AUTOSAR XML (schema 4-2-2)
package /STELLANTIS/EPT/ASWCs
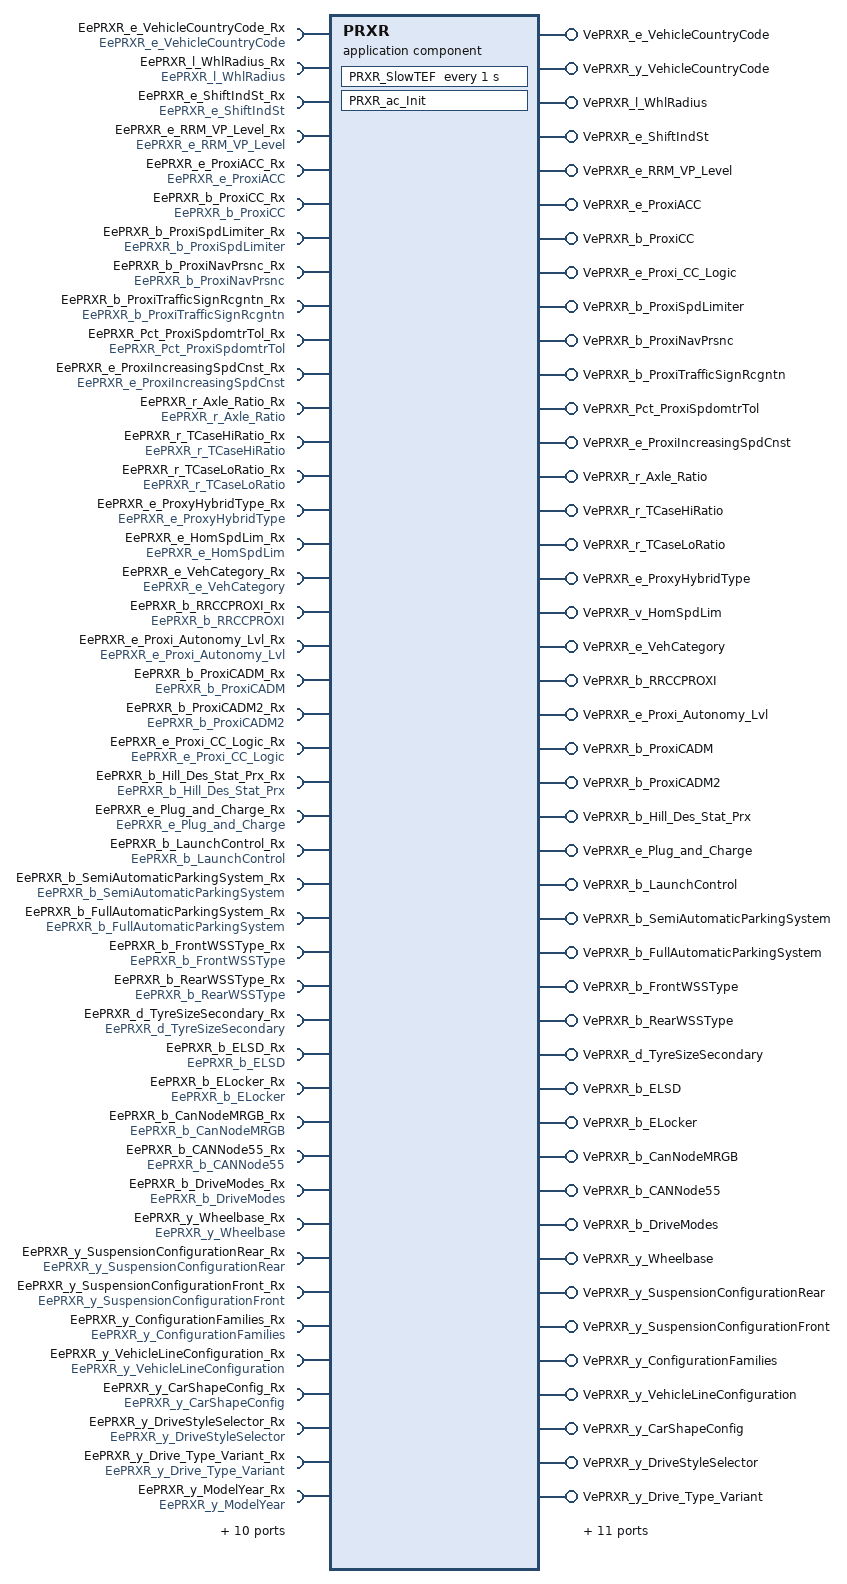
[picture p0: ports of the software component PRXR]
  application sw component type PRXR
    55 x provide port:
      VePRXR_e_VehicleCountryCode: nonqueued-sender-com-spec{data-element=Value, init-value=CePRXR_e_VCC_OTHERS}, provided-interface=VePRXR_e_VehicleCountryCode
      VePRXR_y_VehicleCountryCode: nonqueued-sender-com-spec{data-element=Value, init-value=0}, provided-interface=VePRXR_y_VehicleCountryCode
      VePRXR_l_WhlRadius: nonqueued-sender-com-spec{data-element=Value, init-value=0}, provided-interface=VePRXR_l_WhlRadius
      VePRXR_e_ShiftIndSt: nonqueued-sender-com-spec{data-element=Value, init-value=CePRXR_e_NotPresent}, provided-interface=VePRXR_e_ShiftIndSt
      VePRXR_e_RRM_VP_Level: nonqueued-sender-com-spec{data-element=Value, init-value=CePRXR_e_RRM_VP_Absent}, provided-interface=VePRXR_e_RRM_VP_Level
      VePRXR_e_ProxiACC: nonqueued-sender-com-spec{data-element=Value, init-value=CePRXR_e_ACC_Absent}, provided-interface=VePRXR_e_ProxiACC
      VePRXR_b_ProxiCC: nonqueued-sender-com-spec{data-element=Value, init-value=0}, provided-interface=VePRXR_b_ProxiCC
      VePRXR_e_Proxi_CC_Logic: nonqueued-sender-com-spec{data-element=Value, init-value=CePRXR_e_Logic1}, provided-interface=VePRXR_e_Proxi_CC_Logic
      VePRXR_b_ProxiSpdLimiter: nonqueued-sender-com-spec{data-element=Value, init-value=0}, provided-interface=VePRXR_b_ProxiSpdLimiter
      VePRXR_b_ProxiNavPrsnc: nonqueued-sender-com-spec{data-element=Value, init-value=0}, provided-interface=VePRXR_b_ProxiNavPrsnc
      VePRXR_b_ProxiTrafficSignRcgntn: nonqueued-sender-com-spec{data-element=Value, init-value=0}, provided-interface=VePRXR_b_ProxiTrafficSignRcgntn
      VePRXR_Pct_ProxiSpdomtrTol: nonqueued-sender-com-spec{data-element=Value, init-value=0}, provided-interface=VePRXR_Pct_ProxiSpdomtrTol
      VePRXR_e_ProxiIncreasingSpdCnst: nonqueued-sender-com-spec{data-element=Value, init-value=CePRXR_e_Increasing_0}, provided-interface=VePRXR_e_ProxiIncreasingSpdCnst
      VePRXR_r_Axle_Ratio: nonqueued-sender-com-spec{data-element=Value, init-value=0}, provided-interface=VePRXR_r_Axle_Ratio
      VePRXR_r_TCaseHiRatio: nonqueued-sender-com-spec{data-element=Value, init-value=0}, provided-interface=VePRXR_r_TCaseHiRatio
      VePRXR_r_TCaseLoRatio: nonqueued-sender-com-spec{data-element=Value, init-value=0}, provided-interface=VePRXR_r_TCaseLoRatio
      VePRXR_e_ProxyHybridType: nonqueued-sender-com-spec{data-element=Value, init-value=CePRXR_e_NotApplicable}, provided-interface=VePRXR_e_ProxyHybridType
      VePRXR_v_HomSpdLim: nonqueued-sender-com-spec{data-element=Value, init-value=0}, provided-interface=VePRXR_v_HomSpdLim
      VePRXR_e_VehCategory: nonqueued-sender-com-spec{data-element=Value, init-value=CePRXR_e_Category_M1}, provided-interface=VePRXR_e_VehCategory
      VePRXR_b_RRCCPROXI: nonqueued-sender-com-spec{data-element=Value, init-value=0}, provided-interface=VePRXR_b_RRCCPROXI
      VePRXR_e_Proxi_Autonomy_Lvl: nonqueued-sender-com-spec{data-element=Value, init-value=CePRXR_e_None_Level1}, provided-interface=VePRXR_e_Proxi_Autonomy_Lvl
      VePRXR_b_ProxiCADM: nonqueued-sender-com-spec{data-element=Value, init-value=0}, provided-interface=VePRXR_b_ProxiCADM
      VePRXR_b_ProxiCADM2: nonqueued-sender-com-spec{data-element=Value, init-value=0}, provided-interface=VePRXR_b_ProxiCADM2
      VePRXR_b_Hill_Des_Stat_Prx: nonqueued-sender-com-spec{data-element=Value, init-value=0}, provided-interface=VePRXR_b_Hill_Des_Stat_Prx
      VePRXR_e_Plug_and_Charge: nonqueued-sender-com-spec{data-element=Value, init-value=CePRXR_e_Absent}, provided-interface=VePRXR_e_Plug_and_Charge
      VePRXR_b_LaunchControl: nonqueued-sender-com-spec{data-element=Value, init-value=0}, provided-interface=VePRXR_b_LaunchControl
      VePRXR_b_SemiAutomaticParkingSystem: nonqueued-sender-com-spec{data-element=Value, init-value=0}, provided-interface=VePRXR_b_SemiAutomaticParkingSystem
      VePRXR_b_FullAutomaticParkingSystem: nonqueued-sender-com-spec{data-element=Value, init-value=0}, provided-interface=VePRXR_b_FullAutomaticParkingSystem
      VePRXR_b_FrontWSSType: nonqueued-sender-com-spec{data-element=Value, init-value=0}, provided-interface=VePRXR_b_FrontWSSType
      VePRXR_b_RearWSSType: nonqueued-sender-com-spec{data-element=Value, init-value=0}, provided-interface=VePRXR_b_RearWSSType
      VePRXR_d_TyreSizeSecondary: nonqueued-sender-com-spec{data-element=Value, init-value=0}, provided-interface=VePRXR_d_TyreSizeSecondary
      VePRXR_b_ELSD: nonqueued-sender-com-spec{data-element=Value, init-value=0}, provided-interface=VePRXR_b_ELSD
      VePRXR_b_ELocker: nonqueued-sender-com-spec{data-element=Value, init-value=0}, provided-interface=VePRXR_b_ELocker
      VePRXR_b_CanNodeMRGB: nonqueued-sender-com-spec{data-element=Value, init-value=0}, provided-interface=VePRXR_b_CanNodeMRGB
      VePRXR_b_CANNode55: nonqueued-sender-com-spec{data-element=Value, init-value=0}, provided-interface=VePRXR_b_CANNode55
      VePRXR_b_DriveModes: nonqueued-sender-com-spec{data-element=Value, init-value=0}, provided-interface=VePRXR_b_DriveModes
      VePRXR_y_Wheelbase: nonqueued-sender-com-spec{data-element=Value, init-value=0}, provided-interface=VePRXR_y_Wheelbase
      VePRXR_y_SuspensionConfigurationRear: nonqueued-sender-com-spec{data-element=Value, init-value=0}, provided-interface=VePRXR_y_SuspensionConfigurationRear
      VePRXR_y_SuspensionConfigurationFront: nonqueued-sender-com-spec{data-element=Value, init-value=0}, provided-interface=VePRXR_y_SuspensionConfigurationFront
      VePRXR_y_ConfigurationFamilies: nonqueued-sender-com-spec{data-element=Value, init-value=0}, provided-interface=VePRXR_y_ConfigurationFamilies
      VePRXR_y_VehicleLineConfiguration: nonqueued-sender-com-spec{data-element=Value, init-value=0}, provided-interface=VePRXR_y_VehicleLineConfiguration
      VePRXR_y_CarShapeConfig: nonqueued-sender-com-spec{data-element=Value, init-value=0}, provided-interface=VePRXR_y_CarShapeConfig
      VePRXR_y_DriveStyleSelector: nonqueued-sender-com-spec{data-element=Value, init-value=0}, provided-interface=VePRXR_y_DriveStyleSelector
      VePRXR_y_Drive_Type_Variant: nonqueued-sender-com-spec{data-element=Value, init-value=0}, provided-interface=VePRXR_y_Drive_Type_Variant
      VePRXR_y_ModelYear: nonqueued-sender-com-spec{data-element=Value, init-value=0}, provided-interface=VePRXR_y_ModelYear
      VePRXR_y_Lane_Assist: nonqueued-sender-com-spec{data-element=Value, init-value=0}, provided-interface=VePRXR_y_Lane_Assist
      VePRXR_b_Proxi_Custom_Mode: nonqueued-sender-com-spec{data-element=Value, init-value=0}, provided-interface=VePRXR_b_Proxi_Custom_Mode
      VePRXR_b_Proxi_Track_Mode: nonqueued-sender-com-spec{data-element=Value, init-value=0}, provided-interface=VePRXR_b_Proxi_Track_Mode
      VePRXR_e_Axle_Locker_Presence: nonqueued-sender-com-spec{data-element=Value, init-value=CePRXR_e_ALP_Absent}, provided-interface=VePRXR_e_Axle_Locker_Presence
      VePRXR_e_Terrain_Selector_Modes: nonqueued-sender-com-spec{data-element=Value, init-value=CePRXR_e_Invalid}, provided-interface=VePRXR_e_Terrain_Selector_Modes
      VePRXR_b_V2L_Present: nonqueued-sender-com-spec{data-element=Value, init-value=0}, provided-interface=VePRXR_b_V2L_Present
      VePRXR_e_OnboardPowPanelType: nonqueued-sender-com-spec{data-element=Value, init-value=CePRXR_e_NoType}, provided-interface=VePRXR_e_OnboardPowPanelType
      VePRXR_y_NumOfAGSUnits: nonqueued-sender-com-spec{data-element=Value, init-value=0}, provided-interface=VePRXR_y_NumOfAGSUnits
      VePRXR_e_RWSRackTravelLimits: nonqueued-sender-com-spec{data-element=Value, init-value=CePRXR_e_Limit_0}, provided-interface=VePRXR_e_RWSRackTravelLimits
      VePRXR_b_CanNodeAMP: nonqueued-sender-com-spec{data-element=Value, init-value=0}, provided-interface=VePRXR_b_CanNodeAMP
    54 x require port:
      EePRXR_e_VehicleCountryCode_Rx: nv-require-com-spec{init-value=0, variable=EePRXR_e_VehicleCountryCode}, required-interface=EePRXR_e_VehicleCountryCode
      EePRXR_l_WhlRadius_Rx: nv-require-com-spec{init-value=0, variable=EePRXR_l_WhlRadius}, required-interface=EePRXR_l_WhlRadius
      EePRXR_e_ShiftIndSt_Rx: nv-require-com-spec{init-value=0, variable=EePRXR_e_ShiftIndSt}, required-interface=EePRXR_e_ShiftIndSt
      EePRXR_e_RRM_VP_Level_Rx: nv-require-com-spec{init-value=0, variable=EePRXR_e_RRM_VP_Level}, required-interface=EePRXR_e_RRM_VP_Level
      EePRXR_e_ProxiACC_Rx: nv-require-com-spec{init-value=0, variable=EePRXR_e_ProxiACC}, required-interface=EePRXR_e_ProxiACC
      EePRXR_b_ProxiCC_Rx: nv-require-com-spec{init-value=0, variable=EePRXR_b_ProxiCC}, required-interface=EePRXR_b_ProxiCC
      EePRXR_b_ProxiSpdLimiter_Rx: nv-require-com-spec{init-value=0, variable=EePRXR_b_ProxiSpdLimiter}, required-interface=EePRXR_b_ProxiSpdLimiter
      EePRXR_b_ProxiNavPrsnc_Rx: nv-require-com-spec{init-value=0, variable=EePRXR_b_ProxiNavPrsnc}, required-interface=EePRXR_b_ProxiNavPrsnc
      EePRXR_b_ProxiTrafficSignRcgntn_Rx: nv-require-com-spec{init-value=0, variable=EePRXR_b_ProxiTrafficSignRcgntn}, required-interface=EePRXR_b_ProxiTrafficSignRcgntn
      EePRXR_Pct_ProxiSpdomtrTol_Rx: nv-require-com-spec{init-value=0, variable=EePRXR_Pct_ProxiSpdomtrTol}, required-interface=EePRXR_Pct_ProxiSpdomtrTol
      EePRXR_e_ProxiIncreasingSpdCnst_Rx: nv-require-com-spec{init-value=0, variable=EePRXR_e_ProxiIncreasingSpdCnst}, required-interface=EePRXR_e_ProxiIncreasingSpdCnst
      EePRXR_r_Axle_Ratio_Rx: nv-require-com-spec{init-value=0, variable=EePRXR_r_Axle_Ratio}, required-interface=EePRXR_r_Axle_Ratio
      EePRXR_r_TCaseHiRatio_Rx: nv-require-com-spec{init-value=0, variable=EePRXR_r_TCaseHiRatio}, required-interface=EePRXR_r_TCaseHiRatio
      EePRXR_r_TCaseLoRatio_Rx: nv-require-com-spec{init-value=0, variable=EePRXR_r_TCaseLoRatio}, required-interface=EePRXR_r_TCaseLoRatio
      EePRXR_e_ProxyHybridType_Rx: nv-require-com-spec{init-value=0, variable=EePRXR_e_ProxyHybridType}, required-interface=EePRXR_e_ProxyHybridType
      EePRXR_e_HomSpdLim_Rx: nv-require-com-spec{init-value=0, variable=EePRXR_e_HomSpdLim}, required-interface=EePRXR_e_HomSpdLim
      EePRXR_e_VehCategory_Rx: nv-require-com-spec{init-value=0, variable=EePRXR_e_VehCategory}, required-interface=EePRXR_e_VehCategory
      EePRXR_b_RRCCPROXI_Rx: nv-require-com-spec{init-value=0, variable=EePRXR_b_RRCCPROXI}, required-interface=EePRXR_b_RRCCPROXI
      EePRXR_e_Proxi_Autonomy_Lvl_Rx: nv-require-com-spec{init-value=0, variable=EePRXR_e_Proxi_Autonomy_Lvl}, required-interface=EePRXR_e_Proxi_Autonomy_Lvl
      EePRXR_b_ProxiCADM_Rx: nv-require-com-spec{init-value=0, variable=EePRXR_b_ProxiCADM}, required-interface=EePRXR_b_ProxiCADM
      EePRXR_b_ProxiCADM2_Rx: nv-require-com-spec{init-value=0, variable=EePRXR_b_ProxiCADM2}, required-interface=EePRXR_b_ProxiCADM2
      EePRXR_e_Proxi_CC_Logic_Rx: nv-require-com-spec{init-value=0, variable=EePRXR_e_Proxi_CC_Logic}, required-interface=EePRXR_e_Proxi_CC_Logic
      EePRXR_b_Hill_Des_Stat_Prx_Rx: nv-require-com-spec{init-value=0, variable=EePRXR_b_Hill_Des_Stat_Prx}, required-interface=EePRXR_b_Hill_Des_Stat_Prx
      EePRXR_e_Plug_and_Charge_Rx: nv-require-com-spec{init-value=0, variable=EePRXR_e_Plug_and_Charge}, required-interface=EePRXR_e_Plug_and_Charge
      EePRXR_b_LaunchControl_Rx: nv-require-com-spec{init-value=0, variable=EePRXR_b_LaunchControl}, required-interface=EePRXR_b_LaunchControl
      EePRXR_b_SemiAutomaticParkingSystem_Rx: nv-require-com-spec{init-value=0, variable=EePRXR_b_SemiAutomaticParkingSystem}, required-interface=EePRXR_b_SemiAutomaticParkingSystem
      EePRXR_b_FullAutomaticParkingSystem_Rx: nv-require-com-spec{init-value=0, variable=EePRXR_b_FullAutomaticParkingSystem}, required-interface=EePRXR_b_FullAutomaticParkingSystem
      EePRXR_b_FrontWSSType_Rx: nv-require-com-spec{init-value=0, variable=EePRXR_b_FrontWSSType}, required-interface=EePRXR_b_FrontWSSType
      EePRXR_b_RearWSSType_Rx: nv-require-com-spec{init-value=0, variable=EePRXR_b_RearWSSType}, required-interface=EePRXR_b_RearWSSType
      EePRXR_d_TyreSizeSecondary_Rx: nv-require-com-spec{init-value=0, variable=EePRXR_d_TyreSizeSecondary}, required-interface=EePRXR_d_TyreSizeSecondary
      EePRXR_b_ELSD_Rx: nv-require-com-spec{init-value=0, variable=EePRXR_b_ELSD}, required-interface=EePRXR_b_ELSD
      EePRXR_b_ELocker_Rx: nv-require-com-spec{init-value=0, variable=EePRXR_b_ELocker}, required-interface=EePRXR_b_ELocker
      EePRXR_b_CanNodeMRGB_Rx: nv-require-com-spec{init-value=0, variable=EePRXR_b_CanNodeMRGB}, required-interface=EePRXR_b_CanNodeMRGB
      EePRXR_b_CANNode55_Rx: nv-require-com-spec{init-value=0, variable=EePRXR_b_CANNode55}, required-interface=EePRXR_b_CANNode55
      EePRXR_b_DriveModes_Rx: nv-require-com-spec{init-value=0, variable=EePRXR_b_DriveModes}, required-interface=EePRXR_b_DriveModes
      EePRXR_y_Wheelbase_Rx: nv-require-com-spec{init-value=0, variable=EePRXR_y_Wheelbase}, required-interface=EePRXR_y_Wheelbase
      EePRXR_y_SuspensionConfigurationRear_Rx: nv-require-com-spec{init-value=0, variable=EePRXR_y_SuspensionConfigurationRear}, required-interface=EePRXR_y_SuspensionConfigurationRear
      EePRXR_y_SuspensionConfigurationFront_Rx: nv-require-com-spec{init-value=0, variable=EePRXR_y_SuspensionConfigurationFront}, required-interface=EePRXR_y_SuspensionConfigurationFront
      EePRXR_y_ConfigurationFamilies_Rx: nv-require-com-spec{init-value=0, variable=EePRXR_y_ConfigurationFamilies}, required-interface=EePRXR_y_ConfigurationFamilies
      EePRXR_y_VehicleLineConfiguration_Rx: nv-require-com-spec{init-value=0, variable=EePRXR_y_VehicleLineConfiguration}, required-interface=EePRXR_y_VehicleLineConfiguration
      EePRXR_y_CarShapeConfig_Rx: nv-require-com-spec{init-value=0, variable=EePRXR_y_CarShapeConfig}, required-interface=EePRXR_y_CarShapeConfig
      EePRXR_y_DriveStyleSelector_Rx: nv-require-com-spec{init-value=0, variable=EePRXR_y_DriveStyleSelector}, required-interface=EePRXR_y_DriveStyleSelector
      EePRXR_y_Drive_Type_Variant_Rx: nv-require-com-spec{init-value=0, variable=EePRXR_y_Drive_Type_Variant}, required-interface=EePRXR_y_Drive_Type_Variant
      EePRXR_y_ModelYear_Rx: nv-require-com-spec{init-value=0, variable=EePRXR_y_ModelYear}, required-interface=EePRXR_y_ModelYear
      EePRXR_y_Lane_Assist_Rx: nv-require-com-spec{init-value=0, variable=EePRXR_y_Lane_Assist}, required-interface=EePRXR_y_Lane_Assist
      EePRXR_b_Custom_Mode_Rx: nv-require-com-spec{init-value=0, variable=EePRXR_b_Custom_Mode}, required-interface=EePRXR_b_Custom_Mode
      EePRXR_b_TRACK_Mode_Rx: nv-require-com-spec{init-value=0, variable=EePRXR_b_TRACK_Mode}, required-interface=EePRXR_b_TRACK_Mode
      EePRXR_e_Axle_Locker_Presence_Rx: nv-require-com-spec{init-value=0, variable=EePRXR_e_Axle_Locker_Presence}, required-interface=EePRXR_e_Axle_Locker_Presence
      EePRXR_e_Terrain_Selector_Modes_Rx: nv-require-com-spec{init-value=0, variable=EePRXR_e_Terrain_Selector_Modes}, required-interface=EePRXR_e_Terrain_Selector_Modes
      EePRXR_b_V2L_Present_Rx: nv-require-com-spec{init-value=0, variable=EePRXR_b_V2L_Present}, required-interface=EePRXR_b_V2L_Present
      EePRXR_e_OnboardPowPanelType_Rx: nv-require-com-spec{init-value=0, variable=EePRXR_e_OnboardPowPanelType}, required-interface=EePRXR_e_OnboardPowPanelType
      EePRXR_y_NumOfAGSUnits_Rx: nv-require-com-spec{init-value=0, variable=EePRXR_y_NumOfAGSUnits}, required-interface=EePRXR_y_NumOfAGSUnits
      EePRXR_y_RWSRackTravelLimits_Rx: nv-require-com-spec{init-value=0, variable=EePRXR_y_RWSRackTravelLimits}, required-interface=EePRXR_y_RWSRackTravelLimits
      EePRXR_b_CanNodeAMP_Rx: nv-require-com-spec{init-value=0, variable=EePRXR_b_CanNodeAMP}, required-interface=EePRXR_b_CanNodeAMP
    behavior IB_PRXR: data-type-mapping=msADTtoIDTMapping, handle-termination-and-restart=NO-SUPPORT
      timing event Event_SlowTEF: start-on-event=PRXR_SlowTEF, period=1
      init event Event_PRXR_ac_Init: start-on-event=PRXR_ac_Init
      runnable PRXR_ac_Init
        data-receive-point-by-arguments:
          54 x access:
            IN_EePRXR_Pct_ProxiSpdomtrTol_Rx_EePRXR_Pct_ProxiSpdomtrTol: accessed-variable=EePRXR_Pct_ProxiSpdomtrTol_Rx.EePRXR_Pct_ProxiSpdomtrTol
            IN_EePRXR_b_CANNode55_Rx_EePRXR_b_CANNode55: accessed-variable=EePRXR_b_CANNode55_Rx.EePRXR_b_CANNode55
            IN_EePRXR_b_CanNodeAMP_Rx_EePRXR_b_CanNodeAMP: accessed-variable=EePRXR_b_CanNodeAMP_Rx.EePRXR_b_CanNodeAMP
            IN_EePRXR_b_CanNodeMRGB_Rx_EePRXR_b_CanNodeMRGB: accessed-variable=EePRXR_b_CanNodeMRGB_Rx.EePRXR_b_CanNodeMRGB
            IN_EePRXR_b_Custom_Mode_Rx_EePRXR_b_Custom_Mode: accessed-variable=EePRXR_b_Custom_Mode_Rx.EePRXR_b_Custom_Mode
            IN_EePRXR_b_DriveModes_Rx_EePRXR_b_DriveModes: accessed-variable=EePRXR_b_DriveModes_Rx.EePRXR_b_DriveModes
            IN_EePRXR_b_ELSD_Rx_EePRXR_b_ELSD: accessed-variable=EePRXR_b_ELSD_Rx.EePRXR_b_ELSD
            IN_EePRXR_b_ELocker_Rx_EePRXR_b_ELocker: accessed-variable=EePRXR_b_ELocker_Rx.EePRXR_b_ELocker
            IN_EePRXR_b_FrontWSSType_Rx_EePRXR_b_FrontWSSType: accessed-variable=EePRXR_b_FrontWSSType_Rx.EePRXR_b_FrontWSSType
            IN_EePRXR_b_FullAutomaticParkingSystem_Rx_EePRXR_b_FullAutomaticParkingSystem: accessed-variable=EePRXR_b_FullAutomaticParkingSystem_Rx.EePRXR_b_FullAutomaticParkingSystem
            IN_EePRXR_b_Hill_Des_Stat_Prx_Rx_EePRXR_b_Hill_Des_Stat_Prx: accessed-variable=EePRXR_b_Hill_Des_Stat_Prx_Rx.EePRXR_b_Hill_Des_Stat_Prx
            IN_EePRXR_b_LaunchControl_Rx_EePRXR_b_LaunchControl: accessed-variable=EePRXR_b_LaunchControl_Rx.EePRXR_b_LaunchControl
            IN_EePRXR_b_ProxiCADM2_Rx_EePRXR_b_ProxiCADM2: accessed-variable=EePRXR_b_ProxiCADM2_Rx.EePRXR_b_ProxiCADM2
            IN_EePRXR_b_ProxiCADM_Rx_EePRXR_b_ProxiCADM: accessed-variable=EePRXR_b_ProxiCADM_Rx.EePRXR_b_ProxiCADM
            IN_EePRXR_b_ProxiCC_Rx_EePRXR_b_ProxiCC: accessed-variable=EePRXR_b_ProxiCC_Rx.EePRXR_b_ProxiCC
            IN_EePRXR_b_ProxiNavPrsnc_Rx_EePRXR_b_ProxiNavPrsnc: accessed-variable=EePRXR_b_ProxiNavPrsnc_Rx.EePRXR_b_ProxiNavPrsnc
            IN_EePRXR_b_ProxiSpdLimiter_Rx_EePRXR_b_ProxiSpdLimiter: accessed-variable=EePRXR_b_ProxiSpdLimiter_Rx.EePRXR_b_ProxiSpdLimiter
            IN_EePRXR_b_ProxiTrafficSignRcgntn_Rx_EePRXR_b_ProxiTrafficSignRcgntn: accessed-variable=EePRXR_b_ProxiTrafficSignRcgntn_Rx.EePRXR_b_ProxiTrafficSignRcgntn
            IN_EePRXR_b_RRCCPROXI_Rx_EePRXR_b_RRCCPROXI: accessed-variable=EePRXR_b_RRCCPROXI_Rx.EePRXR_b_RRCCPROXI
            IN_EePRXR_b_RearWSSType_Rx_EePRXR_b_RearWSSType: accessed-variable=EePRXR_b_RearWSSType_Rx.EePRXR_b_RearWSSType
            IN_EePRXR_b_SemiAutomaticParkingSystem_Rx_EePRXR_b_SemiAutomaticParkingSystem: accessed-variable=EePRXR_b_SemiAutomaticParkingSystem_Rx.EePRXR_b_SemiAutomaticParkingSystem
            IN_EePRXR_b_TRACK_Mode_Rx_EePRXR_b_TRACK_Mode: accessed-variable=EePRXR_b_TRACK_Mode_Rx.EePRXR_b_TRACK_Mode
            IN_EePRXR_b_V2L_Present_Rx_EePRXR_b_V2L_Present: accessed-variable=EePRXR_b_V2L_Present_Rx.EePRXR_b_V2L_Present
            IN_EePRXR_d_TyreSizeSecondary_Rx_EePRXR_d_TyreSizeSecondary: accessed-variable=EePRXR_d_TyreSizeSecondary_Rx.EePRXR_d_TyreSizeSecondary
            IN_EePRXR_e_Axle_Locker_Presence_Rx_EePRXR_e_Axle_Locker_Presence: accessed-variable=EePRXR_e_Axle_Locker_Presence_Rx.EePRXR_e_Axle_Locker_Presence
            IN_EePRXR_e_HomSpdLim_Rx_EePRXR_e_HomSpdLim: accessed-variable=EePRXR_e_HomSpdLim_Rx.EePRXR_e_HomSpdLim
            IN_EePRXR_e_OnboardPowPanelType_Rx_EePRXR_e_OnboardPowPanelType: accessed-variable=EePRXR_e_OnboardPowPanelType_Rx.EePRXR_e_OnboardPowPanelType
            IN_EePRXR_e_Plug_and_Charge_Rx_EePRXR_e_Plug_and_Charge: accessed-variable=EePRXR_e_Plug_and_Charge_Rx.EePRXR_e_Plug_and_Charge
            IN_EePRXR_e_ProxiACC_Rx_EePRXR_e_ProxiACC: accessed-variable=EePRXR_e_ProxiACC_Rx.EePRXR_e_ProxiACC
            IN_EePRXR_e_ProxiIncreasingSpdCnst_Rx_EePRXR_e_ProxiIncreasingSpdCnst: accessed-variable=EePRXR_e_ProxiIncreasingSpdCnst_Rx.EePRXR_e_ProxiIncreasingSpdCnst
            IN_EePRXR_e_Proxi_Autonomy_Lvl_Rx_EePRXR_e_Proxi_Autonomy_Lvl: accessed-variable=EePRXR_e_Proxi_Autonomy_Lvl_Rx.EePRXR_e_Proxi_Autonomy_Lvl
            IN_EePRXR_e_Proxi_CC_Logic_Rx_EePRXR_e_Proxi_CC_Logic: accessed-variable=EePRXR_e_Proxi_CC_Logic_Rx.EePRXR_e_Proxi_CC_Logic
            IN_EePRXR_e_ProxyHybridType_Rx_EePRXR_e_ProxyHybridType: accessed-variable=EePRXR_e_ProxyHybridType_Rx.EePRXR_e_ProxyHybridType
            IN_EePRXR_e_RRM_VP_Level_Rx_EePRXR_e_RRM_VP_Level: accessed-variable=EePRXR_e_RRM_VP_Level_Rx.EePRXR_e_RRM_VP_Level
            IN_EePRXR_e_ShiftIndSt_Rx_EePRXR_e_ShiftIndSt: accessed-variable=EePRXR_e_ShiftIndSt_Rx.EePRXR_e_ShiftIndSt
            IN_EePRXR_e_Terrain_Selector_Modes_Rx_EePRXR_e_Terrain_Selector_Modes: accessed-variable=EePRXR_e_Terrain_Selector_Modes_Rx.EePRXR_e_Terrain_Selector_Modes
            IN_EePRXR_e_VehCategory_Rx_EePRXR_e_VehCategory: accessed-variable=EePRXR_e_VehCategory_Rx.EePRXR_e_VehCategory
            IN_EePRXR_e_VehicleCountryCode_Rx_EePRXR_e_VehicleCountryCode: accessed-variable=EePRXR_e_VehicleCountryCode_Rx.EePRXR_e_VehicleCountryCode
            IN_EePRXR_l_WhlRadius_Rx_EePRXR_l_WhlRadius: accessed-variable=EePRXR_l_WhlRadius_Rx.EePRXR_l_WhlRadius
            IN_EePRXR_r_Axle_Ratio_Rx_EePRXR_r_Axle_Ratio: accessed-variable=EePRXR_r_Axle_Ratio_Rx.EePRXR_r_Axle_Ratio
            IN_EePRXR_r_TCaseHiRatio_Rx_EePRXR_r_TCaseHiRatio: accessed-variable=EePRXR_r_TCaseHiRatio_Rx.EePRXR_r_TCaseHiRatio
            IN_EePRXR_r_TCaseLoRatio_Rx_EePRXR_r_TCaseLoRatio: accessed-variable=EePRXR_r_TCaseLoRatio_Rx.EePRXR_r_TCaseLoRatio
            IN_EePRXR_y_CarShapeConfig_Rx_EePRXR_y_CarShapeConfig: accessed-variable=EePRXR_y_CarShapeConfig_Rx.EePRXR_y_CarShapeConfig
            IN_EePRXR_y_ConfigurationFamilies_Rx_EePRXR_y_ConfigurationFamilies: accessed-variable=EePRXR_y_ConfigurationFamilies_Rx.EePRXR_y_ConfigurationFamilies
            IN_EePRXR_y_DriveStyleSelector_Rx_EePRXR_y_DriveStyleSelector: accessed-variable=EePRXR_y_DriveStyleSelector_Rx.EePRXR_y_DriveStyleSelector
            IN_EePRXR_y_Drive_Type_Variant_Rx_EePRXR_y_Drive_Type_Variant: accessed-variable=EePRXR_y_Drive_Type_Variant_Rx.EePRXR_y_Drive_Type_Variant
            IN_EePRXR_y_Lane_Assist_Rx_EePRXR_y_Lane_Assist: accessed-variable=EePRXR_y_Lane_Assist_Rx.EePRXR_y_Lane_Assist
            IN_EePRXR_y_ModelYear_Rx_EePRXR_y_ModelYear: accessed-variable=EePRXR_y_ModelYear_Rx.EePRXR_y_ModelYear
            IN_EePRXR_y_NumOfAGSUnits_Rx_EePRXR_y_NumOfAGSUnits: accessed-variable=EePRXR_y_NumOfAGSUnits_Rx.EePRXR_y_NumOfAGSUnits
            IN_EePRXR_y_RWSRackTravelLimits_Rx_EePRXR_y_RWSRackTravelLimits: accessed-variable=EePRXR_y_RWSRackTravelLimits_Rx.EePRXR_y_RWSRackTravelLimits
            IN_EePRXR_y_SuspensionConfigurationFront_Rx_EePRXR_y_SuspensionConfigurationFront: accessed-variable=EePRXR_y_SuspensionConfigurationFront_Rx.EePRXR_y_SuspensionConfigurationFront
            IN_EePRXR_y_SuspensionConfigurationRear_Rx_EePRXR_y_SuspensionConfigurationRear: accessed-variable=EePRXR_y_SuspensionConfigurationRear_Rx.EePRXR_y_SuspensionConfigurationRear
            IN_EePRXR_y_VehicleLineConfiguration_Rx_EePRXR_y_VehicleLineConfiguration: accessed-variable=EePRXR_y_VehicleLineConfiguration_Rx.EePRXR_y_VehicleLineConfiguration
            IN_EePRXR_y_Wheelbase_Rx_EePRXR_y_Wheelbase: accessed-variable=EePRXR_y_Wheelbase_Rx.EePRXR_y_Wheelbase
        data-send-points:
          55 x access:
            OUT_VePRXR_e_VehicleCountryCode_Value: accessed-variable=VePRXR_e_VehicleCountryCode.Value
            OUT_VePRXR_y_VehicleCountryCode_Value: accessed-variable=VePRXR_y_VehicleCountryCode.Value
            OUT_VePRXR_l_WhlRadius_Value: accessed-variable=VePRXR_l_WhlRadius.Value
            OUT_VePRXR_e_ShiftIndSt_Value: accessed-variable=VePRXR_e_ShiftIndSt.Value
            OUT_VePRXR_e_RRM_VP_Level_Value: accessed-variable=VePRXR_e_RRM_VP_Level.Value
            OUT_VePRXR_e_ProxiACC_Value: accessed-variable=VePRXR_e_ProxiACC.Value
            OUT_VePRXR_b_ProxiCC_Value: accessed-variable=VePRXR_b_ProxiCC.Value
            OUT_VePRXR_b_ProxiSpdLimiter_Value: accessed-variable=VePRXR_b_ProxiSpdLimiter.Value
            OUT_VePRXR_b_ProxiNavPrsnc_Value: accessed-variable=VePRXR_b_ProxiNavPrsnc.Value
            OUT_VePRXR_b_ProxiTrafficSignRcgntn_Value: accessed-variable=VePRXR_b_ProxiTrafficSignRcgntn.Value
            OUT_VePRXR_Pct_ProxiSpdomtrTol_Value: accessed-variable=VePRXR_Pct_ProxiSpdomtrTol.Value
            OUT_VePRXR_e_ProxiIncreasingSpdCnst_Value: accessed-variable=VePRXR_e_ProxiIncreasingSpdCnst.Value
            OUT_VePRXR_r_Axle_Ratio_Value: accessed-variable=VePRXR_r_Axle_Ratio.Value
            OUT_VePRXR_r_TCaseHiRatio_Value: accessed-variable=VePRXR_r_TCaseHiRatio.Value
            OUT_VePRXR_r_TCaseLoRatio_Value: accessed-variable=VePRXR_r_TCaseLoRatio.Value
            OUT_VePRXR_e_ProxyHybridType_Value: accessed-variable=VePRXR_e_ProxyHybridType.Value
            OUT_VePRXR_v_HomSpdLim_Value: accessed-variable=VePRXR_v_HomSpdLim.Value
            OUT_VePRXR_e_VehCategory_Value: accessed-variable=VePRXR_e_VehCategory.Value
            OUT_VePRXR_b_RRCCPROXI_Value: accessed-variable=VePRXR_b_RRCCPROXI.Value
            OUT_VePRXR_e_Proxi_Autonomy_Lvl_Value: accessed-variable=VePRXR_e_Proxi_Autonomy_Lvl.Value
            OUT_VePRXR_b_ProxiCADM_Value: accessed-variable=VePRXR_b_ProxiCADM.Value
            OUT_VePRXR_b_ProxiCADM2_Value: accessed-variable=VePRXR_b_ProxiCADM2.Value
            OUT_VePRXR_e_Proxi_CC_Logic_Value: accessed-variable=VePRXR_e_Proxi_CC_Logic.Value
            OUT_VePRXR_b_Hill_Des_Stat_Prx_Value: accessed-variable=VePRXR_b_Hill_Des_Stat_Prx.Value
            OUT_VePRXR_e_Plug_and_Charge_Value: accessed-variable=VePRXR_e_Plug_and_Charge.Value
            OUT_VePRXR_b_LaunchControl_Value: accessed-variable=VePRXR_b_LaunchControl.Value
            OUT_VePRXR_b_SemiAutomaticParkingSystem_Value: accessed-variable=VePRXR_b_SemiAutomaticParkingSystem.Value
            OUT_VePRXR_b_FullAutomaticParkingSystem_Value: accessed-variable=VePRXR_b_FullAutomaticParkingSystem.Value
            OUT_VePRXR_b_FrontWSSType_Value: accessed-variable=VePRXR_b_FrontWSSType.Value
            OUT_VePRXR_b_RearWSSType_Value: accessed-variable=VePRXR_b_RearWSSType.Value
            OUT_VePRXR_d_TyreSizeSecondary_Value: accessed-variable=VePRXR_d_TyreSizeSecondary.Value
            OUT_VePRXR_b_ELSD_Value: accessed-variable=VePRXR_b_ELSD.Value
            OUT_VePRXR_b_ELocker_Value: accessed-variable=VePRXR_b_ELocker.Value
            OUT_VePRXR_b_CanNodeMRGB_Value: accessed-variable=VePRXR_b_CanNodeMRGB.Value
            OUT_VePRXR_b_CANNode55_Value: accessed-variable=VePRXR_b_CANNode55.Value
            OUT_VePRXR_b_DriveModes_Value: accessed-variable=VePRXR_b_DriveModes.Value
            OUT_VePRXR_y_Wheelbase_Value: accessed-variable=VePRXR_y_Wheelbase.Value
            OUT_VePRXR_y_SuspensionConfigurationRear_Value: accessed-variable=VePRXR_y_SuspensionConfigurationRear.Value
            OUT_VePRXR_y_SuspensionConfigurationFront_Value: accessed-variable=VePRXR_y_SuspensionConfigurationFront.Value
            OUT_VePRXR_y_ConfigurationFamilies_Value: accessed-variable=VePRXR_y_ConfigurationFamilies.Value
            OUT_VePRXR_y_VehicleLineConfiguration_Value: accessed-variable=VePRXR_y_VehicleLineConfiguration.Value
            OUT_VePRXR_y_CarShapeConfig_Value: accessed-variable=VePRXR_y_CarShapeConfig.Value
            OUT_VePRXR_y_DriveStyleSelector_Value: accessed-variable=VePRXR_y_DriveStyleSelector.Value
            OUT_VePRXR_y_Drive_Type_Variant_Value: accessed-variable=VePRXR_y_Drive_Type_Variant.Value
            OUT_VePRXR_y_ModelYear_Value: accessed-variable=VePRXR_y_ModelYear.Value
            OUT_VePRXR_y_Lane_Assist_Value: accessed-variable=VePRXR_y_Lane_Assist.Value
            OUT_VePRXR_b_Proxi_Custom_Mode_Value: accessed-variable=VePRXR_b_Proxi_Custom_Mode.Value
            OUT_VePRXR_b_Proxi_Track_Mode_Value: accessed-variable=VePRXR_b_Proxi_Track_Mode.Value
            OUT_VePRXR_e_Axle_Locker_Presence_Value: accessed-variable=VePRXR_e_Axle_Locker_Presence.Value
            OUT_VePRXR_e_Terrain_Selector_Modes_Value: accessed-variable=VePRXR_e_Terrain_Selector_Modes.Value
            OUT_VePRXR_b_V2L_Present_Value: accessed-variable=VePRXR_b_V2L_Present.Value
            OUT_VePRXR_e_OnboardPowPanelType_Value: accessed-variable=VePRXR_e_OnboardPowPanelType.Value
            OUT_VePRXR_y_NumOfAGSUnits_Value: accessed-variable=VePRXR_y_NumOfAGSUnits.Value
            OUT_VePRXR_e_RWSRackTravelLimits_Value: accessed-variable=VePRXR_e_RWSRackTravelLimits.Value
            OUT_VePRXR_b_CanNodeAMP_Value: accessed-variable=VePRXR_b_CanNodeAMP.Value
      runnable PRXR_SlowTEF
        data-send-points:
          55 x access:
            OUT_VePRXR_e_VehicleCountryCode_Value: accessed-variable=VePRXR_e_VehicleCountryCode.Value
            OUT_VePRXR_y_VehicleCountryCode_Value: accessed-variable=VePRXR_y_VehicleCountryCode.Value
            OUT_VePRXR_l_WhlRadius_Value: accessed-variable=VePRXR_l_WhlRadius.Value
            OUT_VePRXR_e_ShiftIndSt_Value: accessed-variable=VePRXR_e_ShiftIndSt.Value
            OUT_VePRXR_e_RRM_VP_Level_Value: accessed-variable=VePRXR_e_RRM_VP_Level.Value
            OUT_VePRXR_e_ProxiACC_Value: accessed-variable=VePRXR_e_ProxiACC.Value
            OUT_VePRXR_b_ProxiCC_Value: accessed-variable=VePRXR_b_ProxiCC.Value
            OUT_VePRXR_b_ProxiSpdLimiter_Value: accessed-variable=VePRXR_b_ProxiSpdLimiter.Value
            OUT_VePRXR_b_ProxiNavPrsnc_Value: accessed-variable=VePRXR_b_ProxiNavPrsnc.Value
            OUT_VePRXR_b_ProxiTrafficSignRcgntn_Value: accessed-variable=VePRXR_b_ProxiTrafficSignRcgntn.Value
            OUT_VePRXR_Pct_ProxiSpdomtrTol_Value: accessed-variable=VePRXR_Pct_ProxiSpdomtrTol.Value
            OUT_VePRXR_e_ProxiIncreasingSpdCnst_Value: accessed-variable=VePRXR_e_ProxiIncreasingSpdCnst.Value
            OUT_VePRXR_r_Axle_Ratio_Value: accessed-variable=VePRXR_r_Axle_Ratio.Value
            OUT_VePRXR_r_TCaseHiRatio_Value: accessed-variable=VePRXR_r_TCaseHiRatio.Value
            OUT_VePRXR_r_TCaseLoRatio_Value: accessed-variable=VePRXR_r_TCaseLoRatio.Value
            OUT_VePRXR_e_ProxyHybridType_Value: accessed-variable=VePRXR_e_ProxyHybridType.Value
            OUT_VePRXR_v_HomSpdLim_Value: accessed-variable=VePRXR_v_HomSpdLim.Value
            OUT_VePRXR_e_VehCategory_Value: accessed-variable=VePRXR_e_VehCategory.Value
            OUT_VePRXR_b_RRCCPROXI_Value: accessed-variable=VePRXR_b_RRCCPROXI.Value
            OUT_VePRXR_e_Proxi_Autonomy_Lvl_Value: accessed-variable=VePRXR_e_Proxi_Autonomy_Lvl.Value
            OUT_VePRXR_b_ProxiCADM_Value: accessed-variable=VePRXR_b_ProxiCADM.Value
            OUT_VePRXR_e_Proxi_CC_Logic_Value: accessed-variable=VePRXR_e_Proxi_CC_Logic.Value
            OUT_VePRXR_b_Hill_Des_Stat_Prx_Value: accessed-variable=VePRXR_b_Hill_Des_Stat_Prx.Value
            OUT_VePRXR_e_Plug_and_Charge_Value: accessed-variable=VePRXR_e_Plug_and_Charge.Value
            OUT_VePRXR_y_Wheelbase_Value: accessed-variable=VePRXR_y_Wheelbase.Value
            OUT_VePRXR_b_LaunchControl_Value: accessed-variable=VePRXR_b_LaunchControl.Value
            OUT_VePRXR_b_ProxiCADM2_Value: accessed-variable=VePRXR_b_ProxiCADM2.Value
            OUT_VePRXR_y_SuspensionConfigurationRear_Value: accessed-variable=VePRXR_y_SuspensionConfigurationRear.Value
            OUT_VePRXR_y_SuspensionConfigurationFront_Value: accessed-variable=VePRXR_y_SuspensionConfigurationFront.Value
            OUT_VePRXR_y_ConfigurationFamilies_Value: accessed-variable=VePRXR_y_ConfigurationFamilies.Value
            OUT_VePRXR_y_VehicleLineConfiguration_Value: accessed-variable=VePRXR_y_VehicleLineConfiguration.Value
            OUT_VePRXR_y_CarShapeConfig_Value: accessed-variable=VePRXR_y_CarShapeConfig.Value
            OUT_VePRXR_y_DriveStyleSelector_Value: accessed-variable=VePRXR_y_DriveStyleSelector.Value
            OUT_VePRXR_y_Drive_Type_Variant_Value: accessed-variable=VePRXR_y_Drive_Type_Variant.Value
            OUT_VePRXR_y_ModelYear_Value: accessed-variable=VePRXR_y_ModelYear.Value
            OUT_VePRXR_y_Lane_Assist_Value: accessed-variable=VePRXR_y_Lane_Assist.Value
            OUT_VePRXR_b_SemiAutomaticParkingSystem_Value: accessed-variable=VePRXR_b_SemiAutomaticParkingSystem.Value
            OUT_VePRXR_b_FullAutomaticParkingSystem_Value: accessed-variable=VePRXR_b_FullAutomaticParkingSystem.Value
            OUT_VePRXR_b_FrontWSSType_Value: accessed-variable=VePRXR_b_FrontWSSType.Value
            OUT_VePRXR_b_RearWSSType_Value: accessed-variable=VePRXR_b_RearWSSType.Value
            OUT_VePRXR_b_ELSD_Value: accessed-variable=VePRXR_b_ELSD.Value
            OUT_VePRXR_b_ELocker_Value: accessed-variable=VePRXR_b_ELocker.Value
            OUT_VePRXR_b_CanNodeMRGB_Value: accessed-variable=VePRXR_b_CanNodeMRGB.Value
            OUT_VePRXR_b_CANNode55_Value: accessed-variable=VePRXR_b_CANNode55.Value
            OUT_VePRXR_b_DriveModes_Value: accessed-variable=VePRXR_b_DriveModes.Value
            OUT_VePRXR_d_TyreSizeSecondary_Value: accessed-variable=VePRXR_d_TyreSizeSecondary.Value
            OUT_VePRXR_b_Proxi_Custom_Mode_Value: accessed-variable=VePRXR_b_Proxi_Custom_Mode.Value
            OUT_VePRXR_b_Proxi_Track_Mode_Value: accessed-variable=VePRXR_b_Proxi_Track_Mode.Value
            OUT_VePRXR_e_Axle_Locker_Presence_Value: accessed-variable=VePRXR_e_Axle_Locker_Presence.Value
            OUT_VePRXR_e_Terrain_Selector_Modes_Value: accessed-variable=VePRXR_e_Terrain_Selector_Modes.Value
            OUT_VePRXR_b_V2L_Present_Value: accessed-variable=VePRXR_b_V2L_Present.Value
            OUT_VePRXR_e_OnboardPowPanelType_Value: accessed-variable=VePRXR_e_OnboardPowPanelType.Value
            OUT_VePRXR_y_NumOfAGSUnits_Value: accessed-variable=VePRXR_y_NumOfAGSUnits.Value
            OUT_VePRXR_e_RWSRackTravelLimits_Value: accessed-variable=VePRXR_e_RWSRackTravelLimits.Value
            OUT_VePRXR_b_CanNodeAMP_Value: accessed-variable=VePRXR_b_CanNodeAMP.Value
